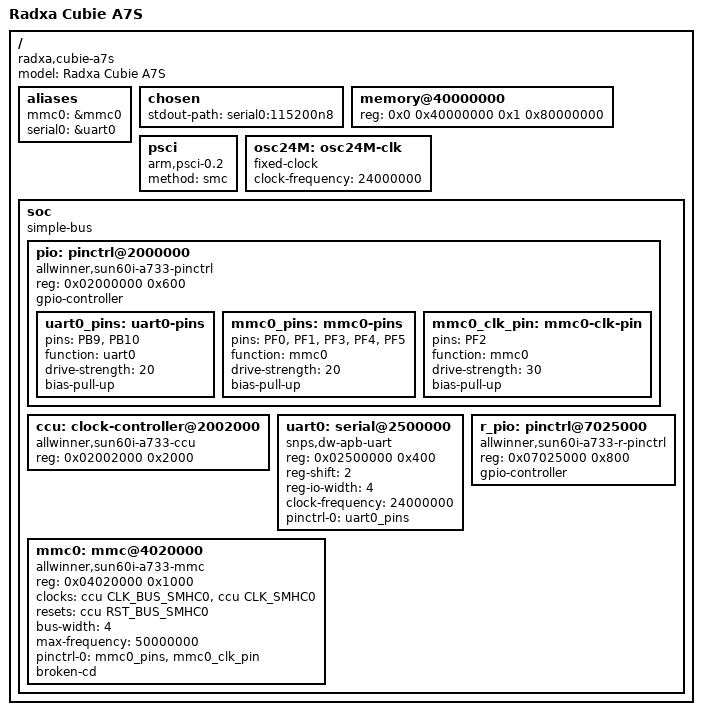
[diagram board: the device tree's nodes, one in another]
// SPDX-License-Identifier: (GPL-2.0+ OR MIT)

/dts-v1/;

#include <dt-bindings/clock/sun60i-a733-ccu.h>
#include <dt-bindings/reset/sun60i-a733-ccu.h>

/ {
	model = "Radxa Cubie A7S";
	compatible = "radxa,cubie-a7s", "allwinner,sun60i-a733";
	#address-cells = <2>;
	#size-cells = <2>;

	aliases {
		mmc0 = &mmc0;
		serial0 = &uart0;
	};

	chosen {
		stdout-path = "serial0:115200n8";
	};

	memory@40000000 {
		device_type = "memory";
		reg = <0x0 0x40000000 0x1 0x80000000>;
	};

	psci {
		compatible = "arm,psci-0.2";
		method = "smc";
	};

	osc24M: osc24M-clk {
		compatible = "fixed-clock";
		#clock-cells = <0>;
		clock-frequency = <24000000>;
	};

	soc {
		compatible = "simple-bus";
		#address-cells = <1>;
		#size-cells = <1>;
		ranges = <0x0 0x0 0x0 0x80000000>;

		pio: pinctrl@2000000 {
			compatible = "allwinner,sun60i-a733-pinctrl";
			reg = <0x02000000 0x600>;
			gpio-controller;
			#gpio-cells = <3>;

			uart0_pins: uart0-pins {
				pins = "PB9", "PB10";
				function = "uart0";
				drive-strength = <20>;
				bias-pull-up;
			};

			mmc0_pins: mmc0-pins {
				pins = "PF0", "PF1", "PF3", "PF4", "PF5";
				function = "mmc0";
				drive-strength = <20>;
				bias-pull-up;
			};

			mmc0_clk_pin: mmc0-clk-pin {
				pins = "PF2";
				function = "mmc0";
				drive-strength = <30>;
				bias-pull-up;
			};
		};

		ccu: clock-controller@2002000 {
			compatible = "allwinner,sun60i-a733-ccu";
			reg = <0x02002000 0x2000>;
			#clock-cells = <1>;
			#reset-cells = <1>;
		};

		uart0: serial@2500000 {
			compatible = "snps,dw-apb-uart";
			reg = <0x02500000 0x400>;
			reg-shift = <2>;
			reg-io-width = <4>;
			clock-frequency = <24000000>;
			pinctrl-names = "default";
			pinctrl-0 = <&uart0_pins>;
			status = "okay";
		};

		mmc0: mmc@4020000 {
			compatible = "allwinner,sun60i-a733-mmc";
			reg = <0x04020000 0x1000>;
			clocks = <&ccu CLK_BUS_SMHC0>, <&ccu CLK_SMHC0>;
			clock-names = "ahb", "mmc";
			resets = <&ccu RST_BUS_SMHC0>;
			reset-names = "ahb";
			bus-width = <4>;
			max-frequency = <50000000>;
			pinctrl-names = "default";
			pinctrl-0 = <&mmc0_pins &mmc0_clk_pin>;
			broken-cd;
			status = "okay";
		};

		r_pio: pinctrl@7025000 {
			compatible = "allwinner,sun60i-a733-r-pinctrl";
			reg = <0x07025000 0x800>;
			gpio-controller;
			#gpio-cells = <3>;
		};
	};
};
